VERSION ""

NS_ :

BS_:

BU_: INERTIAL_MEASUREMENT_UNIT SENSOR_CONTROL_UNIT VEHICLE_CONTORL_UNIT ACCUMULATOR_CONTROL_UNIT MOTOR_CONTROLLER EMUS_BMS
VAL_TABLE_ SWITCH_TOGGLE 1 "TRUE/ON" 0 "FALSE/OFF" ;
VAL_TABLE_ MC_BUS_STATE 1 "CHARGED" 0 "DISCHARGED'" ;
VAL_TABLE_ SET_INVERTER_DISCHARGE 1 "ENABLED" 0 "DISABLED" ;
VAL_TABLE_ SET_INVERTER_ENABLE 1 "ENABLED" 0 "DISABLED" ;
VAL_TABLE_ SET_MC_DIRECTION 1 "FORWARD" 0 "REVERSE" ;
VAL_TABLE_ DriveState 0 "DriveDisabled" ;

BO_ 3221225472 VECTOR__INDEPENDENT_SIG_MSG: 0 Vector__XXX
 SG_ MC_PARAM_COMMAND : 0|8@1- (1,0) [0|0] "" Vector__XXX

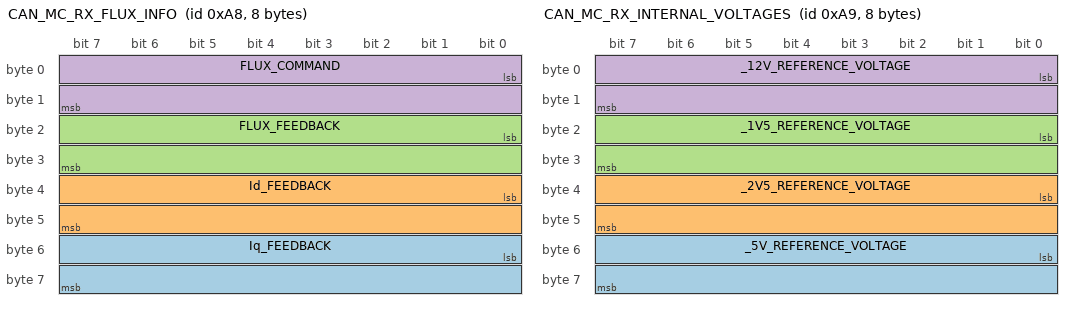
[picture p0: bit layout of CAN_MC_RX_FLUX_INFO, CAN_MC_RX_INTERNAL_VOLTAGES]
BO_ 168 CAN_MC_RX_FLUX_INFO: 8 MOTOR_CONTROLLER
 SG_ Iq_FEEDBACK : 48|16@1- (0.1,48) [-3276.8|3276.7] "AMPS" Vector__XXX
 SG_ Id_FEEDBACK : 32|16@1- (0.1,32) [-3276.8|3276.7] "AMPS" Vector__XXX
 SG_ FLUX_FEEDBACK : 16|16@1- (0.001,16) [-32.768|32] "WEBERS" Vector__XXX
 SG_ FLUX_COMMAND : 0|16@1- (0.001,0) [-32.768|32] "WEBERS" Vector__XXX

BO_ 194 CAN_MC_RESPONSE_MSG: 8 MOTOR_CONTROLLER

BO_ 177 CAN_MC_RX_TORQUE_CAPABILITY: 8 MOTOR_CONTROLLER

BO_ 176 CAN_MC_RX_HIGHSPEED: 8 MOTOR_CONTROLLER

BO_ 175 CAN_MC_RX_DIAGNOSTIC_DATA: 8 MOTOR_CONTROLLER

BO_ 174 CAN_MC_RX_FIRMWARE_INFO: 8 MOTOR_CONTROLLER

BO_ 173 CAN_MC_RX_MODULATION_INDEX: 8 MOTOR_CONTROLLER

BO_ 172 CAN_MC_RX_TORQUE_TIMER_INFO: 8 MOTOR_CONTROLLER

BO_ 171 CAN_MC_RX_FAULT_ID: 8 MOTOR_CONTROLLER

BO_ 170 CAN_MC_RX_INTERNAL_STATES: 8 MOTOR_CONTROLLER

BO_ 169 CAN_MC_RX_INTERNAL_VOLTAGES: 8 MOTOR_CONTROLLER
 SG_ _5V_REFERENCE_VOLTAGE : 48|16@1- (0.01,32) [-327.68|327.67] "V" Vector__XXX
 SG_ _2V5_REFERENCE_VOLTAGE : 32|16@1- (0.01,16) [-327.68|327.67] "V" Vector__XXX
 SG_ _1V5_REFERENCE_VOLTAGE : 16|16@1- (0.01,0) [-327.68|327.67] "V" Vector__XXX
 SG_ _12V_REFERENCE_VOLTAGE : 0|16@1- (0.01,48) [-327.68|327.67] "V" Vector__XXX

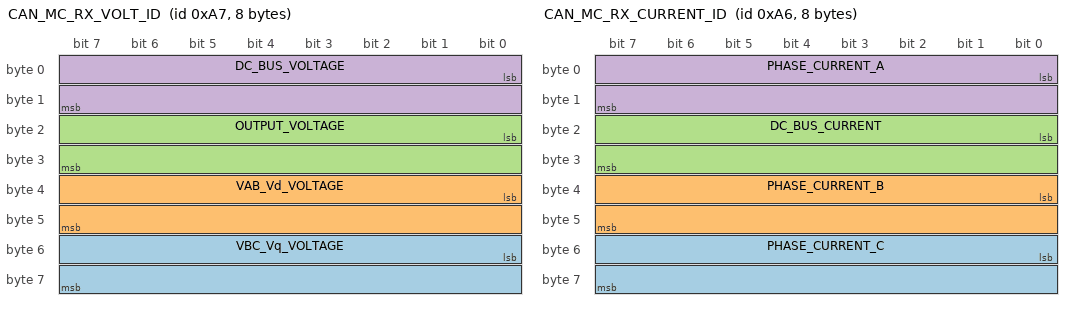
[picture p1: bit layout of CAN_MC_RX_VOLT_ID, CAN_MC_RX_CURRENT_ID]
BO_ 167 CAN_MC_RX_VOLT_ID: 8 MOTOR_CONTROLLER
 SG_ VBC_Vq_VOLTAGE : 48|16@1- (0.1,48) [-3276.8|3276.7] "V" Vector__XXX
 SG_ VAB_Vd_VOLTAGE : 32|16@1- (0.1,32) [-3276.8|3276.7] "V" Vector__XXX
 SG_ OUTPUT_VOLTAGE : 16|16@1- (0.1,16) [-3276.8|3276.7] "V" Vector__XXX
 SG_ DC_BUS_VOLTAGE : 0|16@1- (0.1,0) [-3276.8|3276.7] "V" Vector__XXX

BO_ 166 CAN_MC_RX_CURRENT_ID: 8 MOTOR_CONTROLLER
 SG_ PHASE_CURRENT_C : 48|16@1- (0.1,32) [-3276.8|3276.7] "AMPS" Vector__XXX
 SG_ PHASE_CURRENT_B : 32|16@1- (0.1,16) [-3276.8|3276.7] "AMPS" Vector__XXX
 SG_ DC_BUS_CURRENT : 16|16@1- (0.1,0) [-3276.8|3276.7] "AMPS" Vector__XXX
 SG_ PHASE_CURRENT_A : 0|16@1- (0.1,0) [-3276.8|3276.7] "AMPS" Vector__XXX

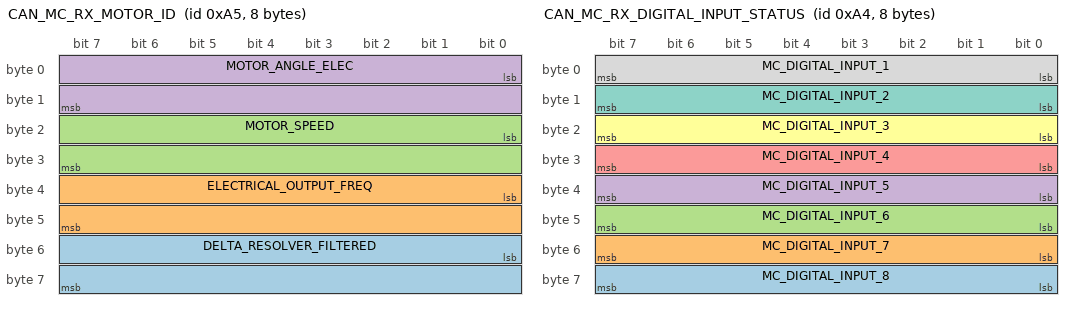
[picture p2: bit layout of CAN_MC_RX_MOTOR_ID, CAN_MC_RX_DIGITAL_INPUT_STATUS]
BO_ 165 CAN_MC_RX_MOTOR_ID: 8 MOTOR_CONTROLLER
 SG_ DELTA_RESOLVER_FILTERED : 48|16@1- (0.1,48) [-359.9|359.9] "DEGREES" Vector__XXX
 SG_ ELECTRICAL_OUTPUT_FREQ : 32|16@1- (0.1,32) [-3276.8|3276.7] "Hz" Vector__XXX
 SG_ MOTOR_SPEED : 16|16@1- (1,16) [-32768|32767] "rpm" Vector__XXX
 SG_ MOTOR_ANGLE_ELEC : 0|16@1- (0.1,0) [-359.9|359.9] "DEGREES" Vector__XXX

BO_ 164 CAN_MC_RX_DIGITAL_INPUT_STATUS: 8 MOTOR_CONTROLLER
 SG_ MC_DIGITAL_INPUT_8 : 56|8@1+ (1,56) [0|1] "" Vector__XXX
 SG_ MC_DIGITAL_INPUT_7 : 48|8@1+ (1,48) [0|1] "" Vector__XXX
 SG_ MC_DIGITAL_INPUT_6 : 40|8@1+ (1,40) [0|1] "" Vector__XXX
 SG_ MC_DIGITAL_INPUT_5 : 32|8@1+ (1,32) [0|1] "" Vector__XXX
 SG_ MC_DIGITAL_INPUT_4 : 24|8@1+ (1,24) [0|1] "" Vector__XXX
 SG_ MC_DIGITAL_INPUT_3 : 16|8@1+ (1,16) [0|1] "" Vector__XXX
 SG_ MC_DIGITAL_INPUT_2 : 8|8@1+ (1,8) [0|1] "" Vector__XXX
 SG_ MC_DIGITAL_INPUT_1 : 0|8@1+ (1,0) [0|1] "" Vector__XXX

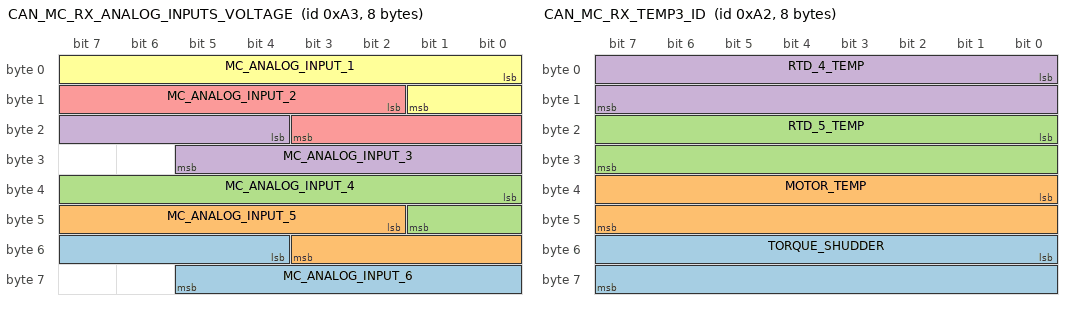
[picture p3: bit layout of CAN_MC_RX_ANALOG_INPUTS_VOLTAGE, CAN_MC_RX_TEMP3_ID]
BO_ 163 CAN_MC_RX_ANALOG_INPUTS_VOLTAGE: 8 MOTOR_CONTROLLER
 SG_ MC_ANALOG_INPUT_6 : 52|10@1- (0.01,52) [-327.68|327.67] "V"  VEHICLE_CONTORL_UNIT
 SG_ MC_ANALOG_INPUT_5 : 42|10@1- (0.01,42) [-327.68|327.67] "V"  VEHICLE_CONTORL_UNIT
 SG_ MC_ANALOG_INPUT_4 : 32|10@1- (0.01,32) [-327.68|327.67] "V"  VEHICLE_CONTORL_UNIT
 SG_ MC_ANALOG_INPUT_3 : 20|10@1- (0.01,20) [-327.68|327.67] "V"  VEHICLE_CONTORL_UNIT
 SG_ MC_ANALOG_INPUT_2 : 10|10@1- (0.01,10) [-327.68|327.67] "V"  VEHICLE_CONTORL_UNIT
 SG_ MC_ANALOG_INPUT_1 : 0|10@1- (0.01,0) [-327.68|327.67] "V"  VEHICLE_CONTORL_UNIT

BO_ 162 CAN_MC_RX_TEMP3_ID: 8 MOTOR_CONTROLLER
 SG_ TORQUE_SHUDDER : 48|16@1- (0.1,48) [-3276.8|3276.7] "Nm"  VEHICLE_CONTORL_UNIT
 SG_ MOTOR_TEMP : 32|16@1- (0.1,32) [-3276.8|3276.7] "DEG_C"  VEHICLE_CONTORL_UNIT
 SG_ RTD_5_TEMP : 16|16@1- (0.1,16) [-3276.8|3276.7] "DEG_C"  VEHICLE_CONTORL_UNIT
 SG_ RTD_4_TEMP : 0|16@1- (0.1,0) [-3276.8|3276.7] "DEG_C"  VEHICLE_CONTORL_UNIT

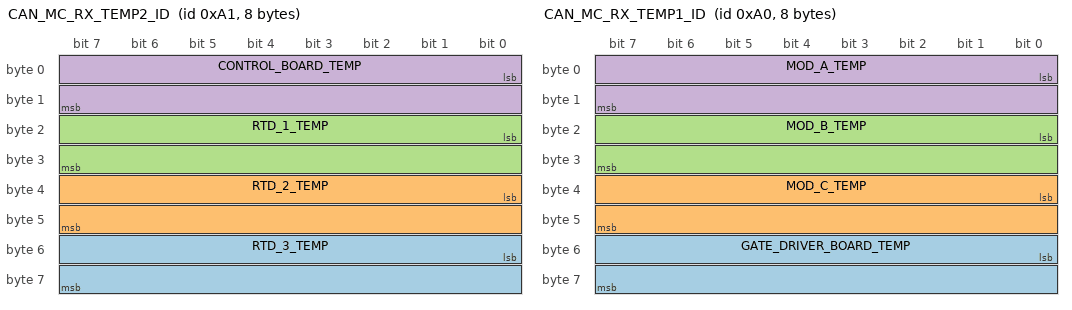
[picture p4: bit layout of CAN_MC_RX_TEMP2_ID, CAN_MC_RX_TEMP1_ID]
BO_ 161 CAN_MC_RX_TEMP2_ID: 8 MOTOR_CONTROLLER
 SG_ RTD_3_TEMP : 48|16@1- (0.1,48) [-3276.8|3276.7] "DEG_C"  VEHICLE_CONTORL_UNIT
 SG_ RTD_2_TEMP : 32|16@1- (0.1,32) [-3276.8|3276.7] "DEG_C"  VEHICLE_CONTORL_UNIT
 SG_ RTD_1_TEMP : 16|16@1- (0.1,16) [-3276.8|3276.7] "DEG_C"  VEHICLE_CONTORL_UNIT
 SG_ CONTROL_BOARD_TEMP : 0|16@1- (0.1,0) [-3276.8|3276.7] "DEG_C"  VEHICLE_CONTORL_UNIT

BO_ 160 CAN_MC_RX_TEMP1_ID: 8 MOTOR_CONTROLLER
 SG_ GATE_DRIVER_BOARD_TEMP : 48|16@1- (0.1,48) [-3276.8|3276.7] "DEG_C"  VEHICLE_CONTORL_UNIT
 SG_ MOD_C_TEMP : 32|16@1- (0.1,32) [-3276.8|3276.7] "DEG_C"  VEHICLE_CONTORL_UNIT
 SG_ MOD_B_TEMP : 16|16@1- (0.1,16) [-3276.8|3276.7] "DEG_C"  VEHICLE_CONTORL_UNIT
 SG_ MOD_A_TEMP : 0|16@1- (0.1,0) [-3276.8|3276.7] "DEG_C"  VEHICLE_CONTORL_UNIT

CM_ BO_ 3221225472 "This is a message for not used signals, created by Vector CANdb++ DBC OLE DB Provider.";
CM_ SG_ 168 Iq_FEEDBACK "Q-axis current feedback ";
CM_ SG_ 168 Id_FEEDBACK "D-axis current feedback ";
CM_ SG_ 167 VBC_Vq_VOLTAGE "Measured value of the voltage between 
Phase B and Phase C (VBC) when the 
inverter is disabled.  Vq voltage when the 
inverter is enabled.";
CM_ SG_ 167 VAB_Vd_VOLTAGE "Measured value of the voltage between 
Phase A and Phase B (VAB) when the 
inverter is disabled.  Vd voltage when the 
inverter is enabled. ";
BA_DEF_  "BusType" STRING ;
BA_DEF_DEF_  "BusType" "CAN";
VAL_ 164 MC_DIGITAL_INPUT_8 1 "TRUE/ON" 0 "FALSE/OFF" ;
VAL_ 164 MC_DIGITAL_INPUT_7 1 "TRUE/ON" 0 "FALSE/OFF" ;
VAL_ 164 MC_DIGITAL_INPUT_6 1 "TRUE/ON" 0 "FALSE/OFF" ;
VAL_ 164 MC_DIGITAL_INPUT_5 1 "TRUE/ON" 0 "FALSE/OFF" ;
VAL_ 164 MC_DIGITAL_INPUT_4 1 "TRUE/ON" 0 "FALSE/OFF" ;
VAL_ 164 MC_DIGITAL_INPUT_3 1 "TRUE/ON" 0 "FALSE/OFF" ;
VAL_ 164 MC_DIGITAL_INPUT_2 1 "TRUE/ON" 0 "FALSE/OFF" ;
VAL_ 164 MC_DIGITAL_INPUT_1 1 "TRUE/ON" 0 "FALSE/OFF" ;
